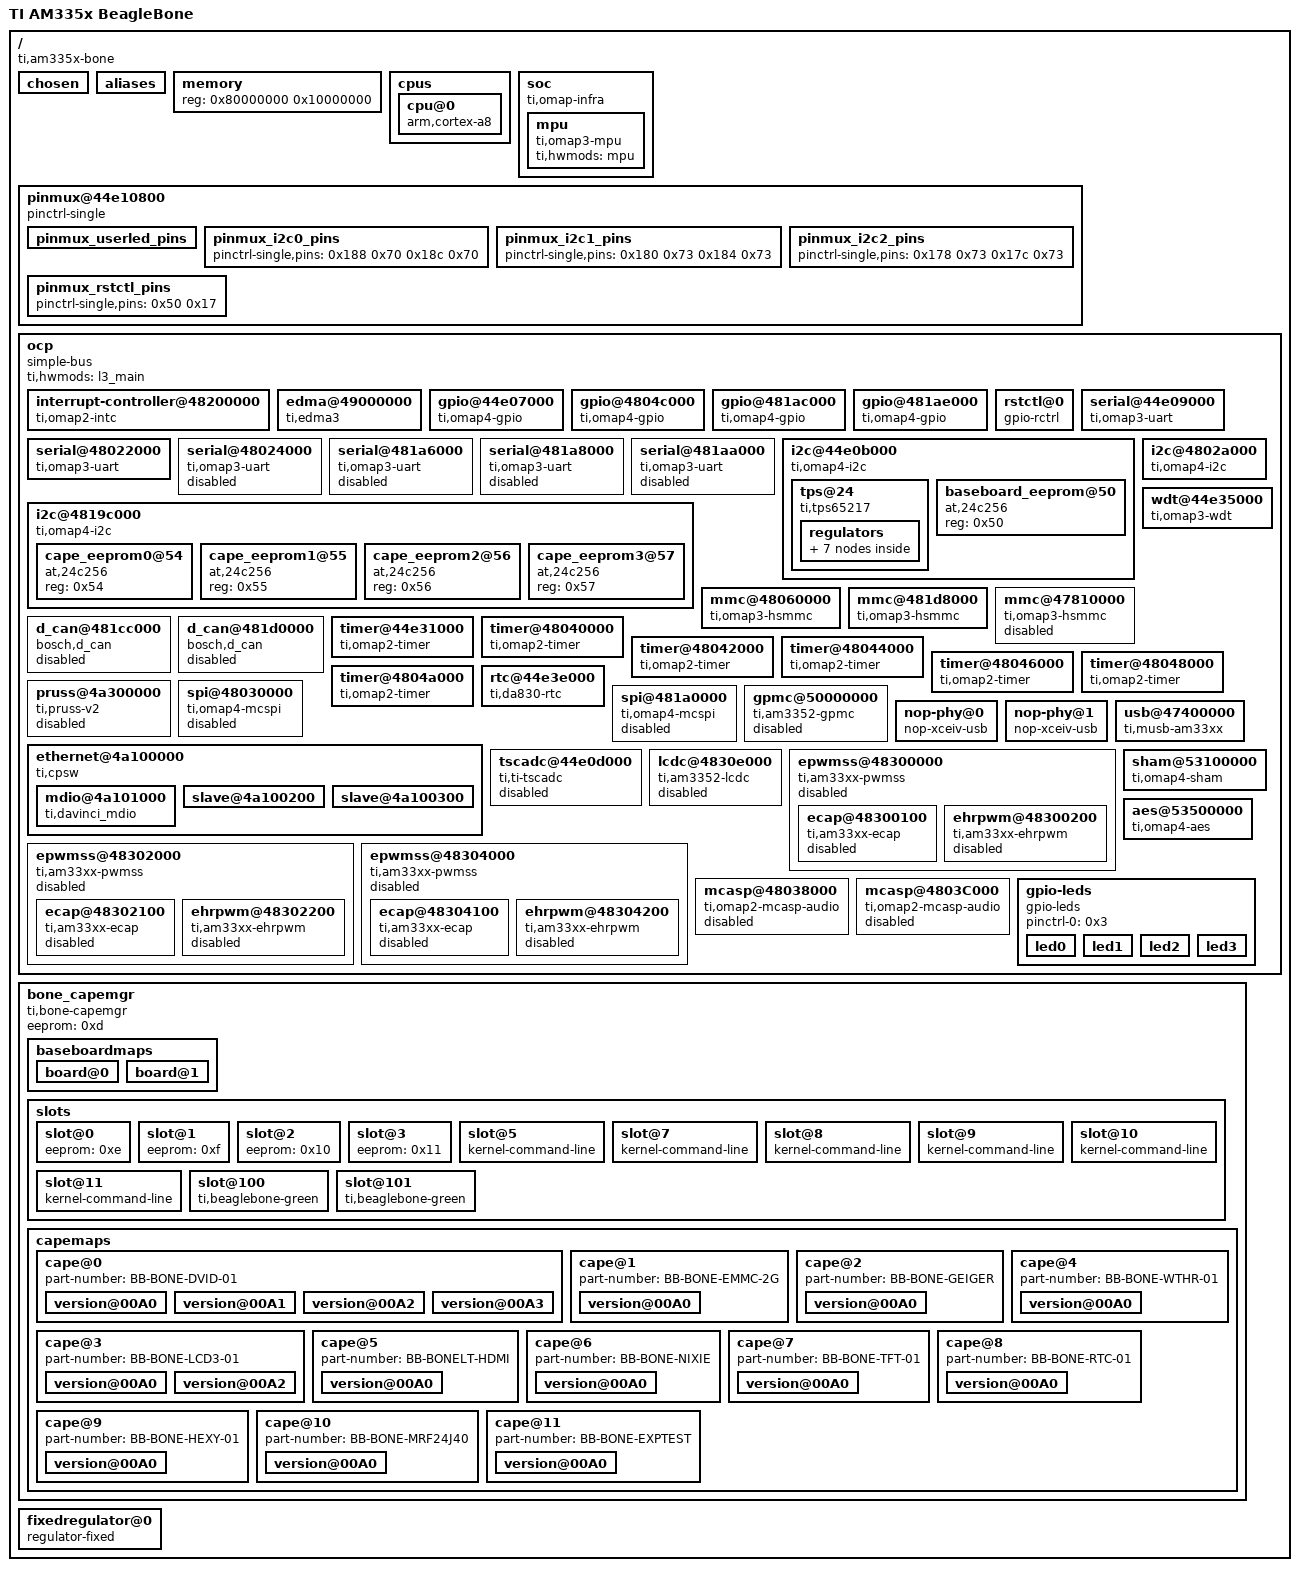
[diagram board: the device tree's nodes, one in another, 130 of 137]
/dts-v1/;

/ {
	#address-cells = <0x1>;
	#size-cells = <0x1>;
	compatible = "ti,am335x-bone", "ti,am33xx";
	interrupt-parent = <0x1>;
	model = "TI AM335x BeagleBone";

	chosen {
	};

	aliases {
		serial0 = "/ocp/serial@44e09000";
		serial1 = "/ocp/serial@48022000";
		serial2 = "/ocp/serial@48024000";
		serial3 = "/ocp/serial@481a6000";
		serial4 = "/ocp/serial@481a8000";
		serial5 = "/ocp/serial@481aa000";
	};

	memory {
		device_type = "memory";
		reg = <0x80000000 0x10000000>;
	};

	cpus {

		cpu@0 {
			compatible = "arm,cortex-a8";
			operating-points = <0xf4240 0x149970 0xc3500 0x13d620 0x927c0 0x10f7c0 0x493e0 0xec928>;
			voltage-tolerance = <0x2>;
			clock-latency = <0x493e0>;
			cpu0-supply = <0x2>;
			linux,phandle = <0x12>;
			phandle = <0x12>;
		};
	};

	soc {
		compatible = "ti,omap-infra";

		mpu {
			compatible = "ti,omap3-mpu";
			ti,hwmods = "mpu";
		};
	};

	pinmux@44e10800 {
		compatible = "pinctrl-single";
		reg = <0x44e10800 0x238>;
		#address-cells = <0x1>;
		#size-cells = <0x0>;
		pinctrl-single,register-width = <0x20>;
		pinctrl-single,function-mask = <0x7f>;
		pinctrl-names = "default";
		pinctrl-0 = <0x3>;
		linux,phandle = <0x13>;
		phandle = <0x13>;

		pinmux_userled_pins {
			pinctrl-single,pins = <0x54 0x7 0x58 0x17 0x5c 0x7 0x60 0x17
// /*PRU1 GPO 0-7*/ 0xa0 0x05 0xa4 0x05 0xa8 0x05 0xac 0x05 0xb0 0x05 0xb4 0x05 0xb8 0x05 0xbc 0x05
/*GPIOrt pins*/ 0x90 0x27 0x94 0x27 0x9c 0x27 0x98 0x27 0x34 0x27 0x30 0x27 0x78 0x27 0x48 0x27 0x3c 0x27 0x38 0x27 0x4c 0x27 0x8c 0x27 0xe0 0x27 0xe8 0x27 0xe4 0x27 0xec 0x27
// /*GPIOrt pins with PRU0 gpo*/ 0x90 0x27 0x94 0x27 0x9c 0x27 0x98 0x27 0x34 0x06 0x30 0x06 0x78 0x27 0x48 0x27 0x3c 0x27 0x38 0x27 0x4c 0x27 0x8c 0x27 0xe0 0x27 0xe8 0x27 0xe4 0x27 0xec 0x27
>;
			linux,phandle = <0x3>;
			phandle = <0x3>;
		};

		pinmux_i2c0_pins {
			pinctrl-single,pins = <0x188 0x70 0x18c 0x70>;
			linux,phandle = <0x6>;
			phandle = <0x6>;
		};

		pinmux_i2c1_pins {
			pinctrl-single,pins = <0x180 0x73 0x184 0x73>;
			linux,phandle = <0x7>;
			phandle = <0x7>;
		};

		pinmux_i2c2_pins {
			pinctrl-single,pins = <0x178 0x73 0x17c 0x73>;
			linux,phandle = <0x8>;
			phandle = <0x8>;
		};

		pinmux_rstctl_pins {
			pinctrl-single,pins = <0x50 0x17>;
			linux,phandle = <0x4>;
			phandle = <0x4>;
		};
	};

	ocp {
		compatible = "simple-bus";
		#address-cells = <0x1>;
		#size-cells = <0x1>;
		ranges;
		ti,hwmods = "l3_main";
		linux,phandle = <0x14>;
		phandle = <0x14>;

		interrupt-controller@48200000 {
			compatible = "ti,omap2-intc";
			interrupt-controller;
			#interrupt-cells = <0x1>;
			ti,intc-size = <0x80>;
			reg = <0x48200000 0x1000>;
			linux,phandle = <0x1>;
			phandle = <0x1>;
		};

		edma@49000000 {
			compatible = "ti,edma3";
			ti,hwmods = "tpcc", "tptc0", "tptc1", "tptc2";
			reg = <0x49000000 0x10000 0x44e10f90 0x40>;
			interrupt-parent = <0x1>;
			interrupts = <0xc 0xd 0xe>;
			#dma-cells = <0x1>;
			dma-channels = <0x40>;
			ti,edma-regions = <0x4>;
			ti,edma-slots = <0x100>;
			ti,edma-queue-tc-map = <0x0 0x0 0x1 0x1 0x2 0x2>;
			ti,edma-queue-priority-map = <0x0 0x0 0x1 0x1 0x2 0x2>;
			ti,edma-default-queue = <0x1>;
			ti,edma-xbar-event-map = <0x20 0xc 0x1e 0x14>;
			linux,phandle = <0x9>;
			phandle = <0x9>;
		};

		gpio@44e07000 {
			compatible = "ti,omap4-gpio";
			ti,hwmods = "gpio1";
			gpio-controller;
			#gpio-cells = <0x2>;
			interrupt-controller;
			#interrupt-cells = <0x1>;
			reg = <0x44e07000 0x1000>;
			interrupts = <0x60>;
			linux,phandle = <0x15>;
			phandle = <0x15>;
		};

		gpio@4804c000 {
			compatible = "ti,omap4-gpio";
			ti,hwmods = "gpio2";
			gpio-controller;
			#gpio-cells = <0x2>;
			interrupt-controller;
			#interrupt-cells = <0x1>;
			reg = <0x4804c000 0x1000>;
			interrupts = <0x62>;
			linux,phandle = <0x5>;
			phandle = <0x5>;
		};

		gpio@481ac000 {
			compatible = "ti,omap4-gpio";
			ti,hwmods = "gpio3";
			gpio-controller;
			#gpio-cells = <0x2>;
			interrupt-controller;
			#interrupt-cells = <0x1>;
			reg = <0x481ac000 0x1000>;
			interrupts = <0x20>;
			linux,phandle = <0x16>;
			phandle = <0x16>;
		};

		gpio@481ae000 {
			compatible = "ti,omap4-gpio";
			ti,hwmods = "gpio4";
			gpio-controller;
			#gpio-cells = <0x2>;
			interrupt-controller;
			#interrupt-cells = <0x1>;
			reg = <0x481ae000 0x1000>;
			interrupts = <0x3e>;
			linux,phandle = <0x17>;
			phandle = <0x17>;
		};

		rstctl@0 {
			status = "okay";
			compatible = "gpio-rctrl";
			pinctrl-names = "default";
			pinctrl-0 = <0x4>;
			#reset-cells = <0x2>;
			gpios = <0x5 0x14 0x0>;
			gpio-names = "eMMC_RSTn";
			linux,phandle = <0xb>;
			phandle = <0xb>;
		};

		serial@44e09000 {
			compatible = "ti,omap3-uart";
			ti,hwmods = "uart1";
			clock-frequency = <0x2dc6c00>;
			reg = <0x44e09000 0x2000>;
			interrupts = <0x48>;
			status = "okay";
			linux,phandle = <0x18>;
			phandle = <0x18>;
		};

		serial@48022000 {
			compatible = "ti,omap3-uart";
			ti,hwmods = "uart2";
			clock-frequency = <0x2dc6c00>;
			reg = <0x48022000 0x2000>;
			interrupts = <0x49>;
			status = "okay";
			linux,phandle = <0x19>;
			phandle = <0x19>;
		};

		serial@48024000 {
			compatible = "ti,omap3-uart";
			ti,hwmods = "uart3";
			clock-frequency = <0x2dc6c00>;
			reg = <0x48024000 0x2000>;
			interrupts = <0x4a>;
			status = "disabled";
			linux,phandle = <0x1a>;
			phandle = <0x1a>;
		};

		serial@481a6000 {
			compatible = "ti,omap3-uart";
			ti,hwmods = "uart4";
			clock-frequency = <0x2dc6c00>;
			reg = <0x481a6000 0x2000>;
			interrupts = <0x2c>;
			status = "disabled";
			linux,phandle = <0x1b>;
			phandle = <0x1b>;
		};

		serial@481a8000 {
			compatible = "ti,omap3-uart";
			ti,hwmods = "uart5";
			clock-frequency = <0x2dc6c00>;
			reg = <0x481a8000 0x2000>;
			interrupts = <0x2d>;
			status = "disabled";
			linux,phandle = <0x1c>;
			phandle = <0x1c>;
		};

		serial@481aa000 {
			compatible = "ti,omap3-uart";
			ti,hwmods = "uart6";
			clock-frequency = <0x2dc6c00>;
			reg = <0x481aa000 0x2000>;
			interrupts = <0x2e>;
			status = "disabled";
			linux,phandle = <0x1d>;
			phandle = <0x1d>;
		};

		i2c@44e0b000 {
			compatible = "ti,omap4-i2c";
			#address-cells = <0x1>;
			#size-cells = <0x0>;
			ti,hwmods = "i2c1";
			reg = <0x44e0b000 0x1000>;
			interrupts = <0x46>;
			status = "okay";
			clock-frequency = <0x61a80>;
			pinctrl-names = "default";
			pinctrl-0 = <0x6>;
			linux,phandle = <0x1e>;
			phandle = <0x1e>;

			tps@24 {
				reg = <0x24>;
				compatible = "ti,tps65217";
				ti,pmic-shutdown-controller;
				linux,phandle = <0x1f>;
				phandle = <0x1f>;

				regulators {
					#address-cells = <0x1>;
					#size-cells = <0x0>;

					regulator@0 {
						reg = <0x0>;
						regulator-compatible = "dcdc1";
						regulator-always-on;
						linux,phandle = <0x20>;
						phandle = <0x20>;
					};

					regulator@1 {
						reg = <0x1>;
						regulator-compatible = "dcdc2";
						regulator-name = "vdd_mpu";
						regulator-min-microvolt = <0xe1d48>;
						regulator-max-microvolt = <0x1437c8>;
						regulator-boot-on;
						regulator-always-on;
						linux,phandle = <0x2>;
						phandle = <0x2>;
					};

					regulator@2 {
						reg = <0x2>;
						regulator-compatible = "dcdc3";
						regulator-name = "vdd_core";
						regulator-min-microvolt = <0xe1d48>;
						regulator-max-microvolt = <0x118c30>;
						regulator-boot-on;
						regulator-always-on;
						linux,phandle = <0x21>;
						phandle = <0x21>;
					};

					regulator@3 {
						reg = <0x3>;
						regulator-compatible = "ldo1";
						regulator-always-on;
						linux,phandle = <0x22>;
						phandle = <0x22>;
					};

					regulator@4 {
						reg = <0x4>;
						regulator-compatible = "ldo2";
						regulator-always-on;
						linux,phandle = <0x23>;
						phandle = <0x23>;
					};

					regulator@5 {
						reg = <0x5>;
						regulator-compatible = "ldo3";
						regulator-min-microvolt = <0x1b7740>;
						regulator-max-microvolt = <0x1b7740>;
						regulator-always-on;
						linux,phandle = <0x24>;
						phandle = <0x24>;
					};

					regulator@6 {
						reg = <0x6>;
						regulator-compatible = "ldo4";
						regulator-always-on;
						linux,phandle = <0x25>;
						phandle = <0x25>;
					};
				};
			};

			baseboard_eeprom@50 {
				compatible = "at,24c256";
				reg = <0x50>;
				linux,phandle = <0xd>;
				phandle = <0xd>;
			};
		};

		i2c@4802a000 {
			compatible = "ti,omap4-i2c";
			#address-cells = <0x1>;
			#size-cells = <0x0>;
			ti,hwmods = "i2c2";
			reg = <0x4802a000 0x1000>;
			interrupts = <0x47>;
			status = "okay";
			pinctrl-names = "default";
			pinctrl-0 = <0x7>;
			clock-frequency = <0x61a80>;
			linux,phandle = <0x26>;
			phandle = <0x26>;
		};

		i2c@4819c000 {
			compatible = "ti,omap4-i2c";
			#address-cells = <0x1>;
			#size-cells = <0x0>;
			ti,hwmods = "i2c3";
			reg = <0x4819c000 0x1000>;
			interrupts = <0x1e>;
			status = "okay";
			pinctrl-names = "default";
			pinctrl-0 = <0x8>;
			clock-frequency = <0x186a0>;
			linux,phandle = <0x27>;
			phandle = <0x27>;

			cape_eeprom0@54 {
				compatible = "at,24c256";
				reg = <0x54>;
				linux,phandle = <0xe>;
				phandle = <0xe>;
			};

			cape_eeprom1@55 {
				compatible = "at,24c256";
				reg = <0x55>;
				linux,phandle = <0xf>;
				phandle = <0xf>;
			};

			cape_eeprom2@56 {
				compatible = "at,24c256";
				reg = <0x56>;
				linux,phandle = <0x10>;
				phandle = <0x10>;
			};

			cape_eeprom3@57 {
				compatible = "at,24c256";
				reg = <0x57>;
				linux,phandle = <0x11>;
				phandle = <0x11>;
			};
		};

		mmc@48060000 {
			compatible = "ti,omap3-hsmmc";
			ti,hwmods = "mmc1";
			ti,dual-volt;
			ti,needs-special-reset;
			ti,needs-special-hs-handling;
			dmas = <0x9 0x18 0x9 0x19>;
			dma-names = "tx", "rx";
			status = "okay";
			vmmc-supply = <0xa>;
			ti,vcc-aux-disable-is-sleep;
			linux,phandle = <0x28>;
			phandle = <0x28>;
		};

		mmc@481d8000 {
			compatible = "ti,omap3-hsmmc";
			ti,hwmods = "mmc2";
			ti,needs-special-reset;
			ti,needs-special-hs-handling;
			dmas = <0x9 0x2 0x9 0x3>;
			dma-names = "tx", "rx";
			status = "okay";
			vmmc-supply = <0xa>;
			bus-width = <0x8>;
			ti,non-removable;
			reset = <0xb 0x0 0x0>;
			reset-names = "eMMC_RSTn-CONSUMER";
			linux,phandle = <0x29>;
			phandle = <0x29>;
		};

		mmc@47810000 {
			compatible = "ti,omap3-hsmmc";
			ti,hwmods = "mmc3";
			ti,needs-special-reset;
			ti,needs-special-hs-handling;
			status = "disabled";
			linux,phandle = <0x2a>;
			phandle = <0x2a>;
		};

		wdt@44e35000 {
			compatible = "ti,omap3-wdt";
			ti,hwmods = "wd_timer2";
			reg = <0x44e35000 0x1000>;
			interrupts = <0x5b>;
			linux,phandle = <0x2b>;
			phandle = <0x2b>;
		};

		d_can@481cc000 {
			compatible = "bosch,d_can";
			ti,hwmods = "d_can0";
			reg = <0x481cc000 0x2000>;
			interrupts = <0x34>;
			status = "disabled";
			linux,phandle = <0x2c>;
			phandle = <0x2c>;
		};

		d_can@481d0000 {
			compatible = "bosch,d_can";
			ti,hwmods = "d_can1";
			reg = <0x481d0000 0x2000>;
			interrupts = <0x37>;
			status = "disabled";
			linux,phandle = <0x2d>;
			phandle = <0x2d>;
		};

		timer@44e31000 {
			compatible = "ti,omap2-timer";
			reg = <0x44e31000 0x400>;
			interrupts = <0x43>;
			ti,hwmods = "timer1";
			ti,timer-alwon;
			linux,phandle = <0x2e>;
			phandle = <0x2e>;
		};

		timer@48040000 {
			compatible = "ti,omap2-timer";
			reg = <0x48040000 0x400>;
			interrupts = <0x44>;
			ti,hwmods = "timer2";
			linux,phandle = <0x2f>;
			phandle = <0x2f>;
		};

		timer@48042000 {
			compatible = "ti,omap2-timer";
			reg = <0x48042000 0x400>;
			interrupts = <0x45>;
			ti,hwmods = "timer3";
			linux,phandle = <0x30>;
			phandle = <0x30>;
		};

		timer@48044000 {
			compatible = "ti,omap2-timer";
			reg = <0x48044000 0x400>;
			interrupts = <0x5c>;
			ti,hwmods = "timer4";
			ti,timer-pwm;
			linux,phandle = <0x31>;
			phandle = <0x31>;
		};

		timer@48046000 {
			compatible = "ti,omap2-timer";
			reg = <0x48046000 0x400>;
			interrupts = <0x5d>;
			ti,hwmods = "timer5";
			ti,timer-pwm;
			linux,phandle = <0x32>;
			phandle = <0x32>;
		};

		timer@48048000 {
			compatible = "ti,omap2-timer";
			reg = <0x48048000 0x400>;
			interrupts = <0x5e>;
			ti,hwmods = "timer6";
			ti,timer-pwm;
			linux,phandle = <0x33>;
			phandle = <0x33>;
		};

		timer@4804a000 {
			compatible = "ti,omap2-timer";
			reg = <0x4804a000 0x400>;
			interrupts = <0x5f>;
			ti,hwmods = "timer7";
			ti,timer-pwm;
			linux,phandle = <0x34>;
			phandle = <0x34>;
		};

		pruss@4a300000 {
			compatible = "ti,pruss-v2";
			ti,hwmods = "pruss";
			ti,deassert-hard-reset = "pruss", "pruss";
			reg = <0x4a300000 0x80000>;
			ti,pintc-offset = <0x20000>;
			interrupt-parent = <0x1>;
			status = "disabled";
			interrupts = <0x14 0x15 0x16 0x17 0x18 0x19 0x1a 0x1b>;
			linux,phandle = <0x35>;
			phandle = <0x35>;
		};

		rtc@44e3e000 {
			compatible = "ti,da830-rtc";
			reg = <0x44e3e000 0x1000>;
			interrupts = <0x4b 0x4c>;
			ti,hwmods = "rtc";
			ti,system-power-controller;
		};

		spi@48030000 {
			compatible = "ti,omap4-mcspi";
			#address-cells = <0x1>;
			#size-cells = <0x0>;
			reg = <0x48030000 0x400>;
			interrupt = <0x41>;
			ti,spi-num-cs = <0x2>;
			ti,hwmods = "spi0";
			dmas = <0x9 0x10 0x9 0x11 0x9 0x12 0x9 0x13>;
			dma-names = "tx0", "rx0", "tx1", "rx1";
			status = "disabled";
			linux,phandle = <0x36>;
			phandle = <0x36>;
		};

		spi@481a0000 {
			compatible = "ti,omap4-mcspi";
			#address-cells = <0x1>;
			#size-cells = <0x0>;
			reg = <0x481a0000 0x400>;
			interrupt = <0x7d>;
			ti,spi-num-cs = <0x2>;
			ti,hwmods = "spi1";
			dmas = <0x9 0x2a 0x9 0x2b 0x9 0x2c 0x9 0x2d>;
			dma-names = "tx0", "rx0", "tx1", "rx1";
			status = "disabled";
			linux,phandle = <0x37>;
			phandle = <0x37>;
		};

		gpmc@50000000 {
			compatible = "ti,am3352-gpmc";
			ti,hwmods = "gpmc";
			reg = <0x50000000 0x1000000>;
			interrupts = <0x64>;
			gpmc,num-cs = <0x7>;
			gpmc,num-waitpins = <0x2>;
			#address-cells = <0x2>;
			#size-cells = <0x1>;
			status = "disabled";
			linux,phandle = <0x38>;
			phandle = <0x38>;
		};

		nop-phy@0 {
			compatible = "nop-xceiv-usb";
		};

		nop-phy@1 {
			compatible = "nop-xceiv-usb";
		};

		usb@47400000 {
			compatible = "ti,musb-am33xx";
			reg = <0x47400000 0x1000 0x47401000 0x800 0x47401800 0x800>;
			interrupts = <0x11 0x12 0x13>;
			multipoint = <0x1>;
			num-eps = <0x10>;
			ram-bits = <0xc>;
			port0-mode = <0x3>;
			port1-mode = <0x1>;
			power = <0xfa>;
			ti,hwmods = "usb_otg_hs";
			status = "okay";
			interface_type = <0x1>;
			linux,phandle = <0x39>;
			phandle = <0x39>;
		};

		ethernet@4a100000 {
			compatible = "ti,cpsw";
			ti,hwmods = "cpgmac0";
			cpdma_channels = <0x8>;
			ale_entries = <0x400>;
			bd_ram_size = <0x2000>;
			no_bd_ram = <0x0>;
			rx_descs = <0x40>;
			mac_control = <0x20>;
			slaves = <0x2>;
			cpts_active_slave = <0x0>;
			cpts_clock_mult = <0x80000000>;
			cpts_clock_shift = <0x1d>;
			reg = <0x4a100000 0x800 0x4a101200 0x100>;
			#address-cells = <0x1>;
			#size-cells = <0x1>;
			interrupt-parent = <0x1>;
			interrupts = <0x28 0x29 0x2a 0x2b>;
			ranges;
			disable-napi;
			linux,phandle = <0x3a>;
			phandle = <0x3a>;

			mdio@4a101000 {
				compatible = "ti,davinci_mdio";
				#address-cells = <0x1>;
				#size-cells = <0x0>;
				ti,hwmods = "davinci_mdio";
				bus_freq = <0xf4240>;
				reg = <0x4a101000 0x100>;
				linux,phandle = <0xc>;
				phandle = <0xc>;
			};

			slave@4a100200 {
				mac-address = [00 00 00 00 00 00];
				phy_id = <0xc 0x0>;
				linux,phandle = <0x3b>;
				phandle = <0x3b>;
			};

			slave@4a100300 {
				mac-address = [00 00 00 00 00 00];
				phy_id = <0xc 0x1>;
				linux,phandle = <0x3c>;
				phandle = <0x3c>;
			};
		};

		tscadc@44e0d000 {
			compatible = "ti,ti-tscadc";
			reg = <0x44e0d000 0x1000>;
			interrupt-parent = <0x1>;
			interrupts = <0x10>;
			ti,hwmods = "adc_tsc";
			status = "disabled";
			linux,phandle = <0x3d>;
			phandle = <0x3d>;
		};

		lcdc@4830e000 {
			compatible = "ti,am3352-lcdc", "ti,da830-lcdc";
			reg = <0x4830e000 0x1000>;
			interrupts = <0x24>;
			status = "disabled";
			ti,hwmods = "lcdc";
			linux,phandle = <0x3e>;
			phandle = <0x3e>;
		};

		epwmss@48300000 {
			compatible = "ti,am33xx-pwmss";
			reg = <0x48300000 0x10>;
			ti,hwmods = "epwmss0";
			#address-cells = <0x1>;
			#size-cells = <0x1>;
			status = "disabled";
			ranges = <0x48300100 0x48300100 0x80 0x48300180 0x48300180 0x80 0x48300200 0x48300200 0x80>;
			linux,phandle = <0x3f>;
			phandle = <0x3f>;

			ecap@48300100 {
				compatible = "ti,am33xx-ecap";
				#pwm-cells = <0x3>;
				reg = <0x48300100 0x80>;
				ti,hwmods = "ecap0";
				status = "disabled";
				linux,phandle = <0x40>;
				phandle = <0x40>;
			};

			ehrpwm@48300200 {
				compatible = "ti,am33xx-ehrpwm";
				#pwm-cells = <0x3>;
				reg = <0x48300200 0x80>;
				ti,hwmods = "ehrpwm0";
				status = "disabled";
				linux,phandle = <0x41>;
				phandle = <0x41>;
			};
		};

		epwmss@48302000 {
			compatible = "ti,am33xx-pwmss";
			reg = <0x48302000 0x10>;
			ti,hwmods = "epwmss1";
			#address-cells = <0x1>;
			#size-cells = <0x1>;
			status = "disabled";
			ranges = <0x48302100 0x48302100 0x80 0x48302180 0x48302180 0x80 0x48302200 0x48302200 0x80>;
			linux,phandle = <0x42>;
			phandle = <0x42>;

			ecap@48302100 {
				compatible = "ti,am33xx-ecap";
				#pwm-cells = <0x3>;
				reg = <0x48302100 0x80>;
				ti,hwmods = "ecap1";
				status = "disabled";
				linux,phandle = <0x43>;
				phandle = <0x43>;
			};

			ehrpwm@48302200 {
				compatible = "ti,am33xx-ehrpwm";
				#pwm-cells = <0x3>;
				reg = <0x48302200 0x80>;
				ti,hwmods = "ehrpwm1";
				status = "disabled";
				linux,phandle = <0x44>;
				phandle = <0x44>;
			};
		};

		epwmss@48304000 {
			compatible = "ti,am33xx-pwmss";
			reg = <0x48304000 0x10>;
			ti,hwmods = "epwmss2";
			#address-cells = <0x1>;
			#size-cells = <0x1>;
			status = "disabled";
			ranges = <0x48304100 0x48304100 0x80 0x48304180 0x48304180 0x80 0x48304200 0x48304200 0x80>;
			linux,phandle = <0x45>;
			phandle = <0x45>;

			ecap@48304100 {
				compatible = "ti,am33xx-ecap";
				#pwm-cells = <0x3>;
				reg = <0x48304100 0x80>;
				ti,hwmods = "ecap2";
				status = "disabled";
				linux,phandle = <0x46>;
				phandle = <0x46>;
			};

			ehrpwm@48304200 {
				compatible = "ti,am33xx-ehrpwm";
				#pwm-cells = <0x3>;
				reg = <0x48304200 0x80>;
				ti,hwmods = "ehrpwm2";
				status = "disabled";
				linux,phandle = <0x47>;
				phandle = <0x47>;
			};
		};

		sham@53100000 {
			compatible = "ti,omap4-sham";
			ti,hwmods = "sham";
			#address-cells = <0x1>;
			#size-cells = <0x0>;
			reg = <0x53100000 0x200>;
			interrupt-parent = <0x1>;
			interrupts = <0x6d>;
			dmas = <0x9 0x24>;
			dma-names = "rx";
			status = "okay";
			linux,phandle = <0x48>;
			phandle = <0x48>;
		};

		aes@53500000 {
			compatible = "ti,omap4-aes";
			ti,hwmods = "aes";
			#address-cells = <0x1>;
			#size-cells = <0x0>;
			reg = <0x53500000 0xa0>;
			interrupt-parent = <0x1>;
			interrupts = <0x66>;
			dmas = <0x9 0x6 0x9 0x5>;
			dma-names = "tx", "rx";
			status = "okay";
			linux,phandle = <0x49>;
			phandle = <0x49>;
		};

		mcasp@48038000 {
			compatible = "ti,omap2-mcasp-audio";
			#address-cells = <0x1>;
			#size-cells = <0x0>;
			ti,hwmods = "mcasp0";
			reg = <0x48038000 0x2000>;
			interrupts = <0x50 0x51>;
			status = "disabled";
			asp-chan-q = <0x2>;
			tx-dma-offset = <0x46000000>;
			rx-dma-offset = <0x46000000>;
			dmas = <0x9 0x8 0x9 0x9>;
			dma-names = "tx", "rx";
			linux,phandle = <0x4a>;
			phandle = <0x4a>;
		};

		mcasp@4803C000 {
			compatible = "ti,omap2-mcasp-audio";
			#address-cells = <0x1>;
			#size-cells = <0x0>;
			ti,hwmods = "mcasp1";
			reg = <0x4803c000 0x2000>;
			interrupts = <0x52 0x53>;
			status = "disabled";
			asp-chan-q = <0x2>;
			tx-dma-offset = <0x46400000>;
			rx-dma-offset = <0x46400000>;
			dmas = <0x9 0xa 0x9 0xb>;
			dma-names = "tx", "rx";
			linux,phandle = <0x4b>;
			phandle = <0x4b>;
		};

		gpio-leds {
			compatible = "gpio-leds";
			pinctrl-names = "default";
			pinctrl-0 = <0x3>;

			led0 {
				label = "beaglebone:green:usr0";
				gpios = <0x5 0x15 0x0>;
				linux,default-trigger = "heartbeat";
				default-state = "off";
			};

			led1 {
				label = "beaglebone:green:usr1";
				gpios = <0x5 0x16 0x0>;
				linux,default-trigger = "mmc0";
				default-state = "off";
			};

			led2 {
				label = "beaglebone:green:usr2";
				gpios = <0x5 0x17 0x0>;
				linux,default-trigger = "cpu0";
				default-state = "off";
			};

			led3 {
				label = "beaglebone:green:usr3";
				gpios = <0x5 0x18 0x0>;
				default-state = "off";
				linux,default-trigger = "mmc1";
			};
		};
	};

	bone_capemgr {
		compatible = "ti,bone-capemgr";
		status = "okay";
		eeprom = <0xd>;

		baseboardmaps {

			board@0 {
				board-name = "A335BONE";
				compatible-name = "ti,beaglebone";
				linux,phandle = <0x4c>;
				phandle = <0x4c>;
			};

			board@1 {
				board-name = "A335BNLT";
				compatible-name = "ti,beaglebone-green";
				linux,phandle = <0x4d>;
				phandle = <0x4d>;
			};
		};

		slots {

			slot@0 {
				eeprom = <0xe>;
			};

			slot@1 {
				eeprom = <0xf>;
			};

			slot@2 {
				eeprom = <0x10>;
			};

			slot@3 {
				eeprom = <0x11>;
			};

			slot@5 {
				ti,cape-override;
				compatible = "kernel-command-line", "runtime";
				board-name = "Bone-Geiger";
				version = "00A0";
				manufacturer = "Geiger Inc.";
				part-number = "BB-BONE-GEIGER";
			};

			slot@7 {
				ti,cape-override;
				compatible = "kernel-command-line", "runtime";
				board-name = "Bone-Nixie";
				version = "00A0";
				manufacturer = "Ranostay Industries";
				part-number = "BB-BONE-NIXIE";
			};

			slot@8 {
				ti,cape-override;
				compatible = "kernel-command-line", "runtime";
				board-name = "Bone-TFT";
				version = "00A0";
				manufacturer = "Adafruit";
				part-number = "BB-BONE-TFT-01";
			};

			slot@9 {
				ti,cape-override;
				compatible = "kernel-command-line", "runtime";
				board-name = "Bone-RTC";
				version = "00A0";
				manufacturer = "Adafruit";
				part-number = "BB-BONE-RTC-01";
			};

			slot@10 {
				ti,cape-override;
				compatible = "kernel-command-line", "runtime";
				board-name = "Bone-Hexy";
				version = "00A0";
				manufacturer = "Koen Kooi";
				part-number = "BB-BONE-HEXY-01";
			};

			slot@11 {
				ti,cape-override;
				compatible = "kernel-command-line", "runtime";
				board-name = "Bone-MRF24J40";
				version = "00A0";
				manufacturer = "Signal 11 Software";
				part-number = "BB-BONE-MRF24J40";
			};

			slot@100 {
				ti,cape-override;
				priority = <0x1>;
				compatible = "ti,beaglebone-green";
				board-name = "Bone-LT-eMMC-2G";
				version = "00A0";
				manufacturer = "Texas Instruments";
				part-number = "BB-BONE-EMMC-2G";
			};

			slot@101 {
				ti,cape-override;
				priority = <0x1>;
				compatible = "ti,beaglebone-green";
				board-name = "Bone-Black-HDMI";
				version = "00A0";
				manufacturer = "Texas Instruments";
				part-number = "BB-BONELT-HDMI";
			};
		};

		capemaps {

			cape@0 {
				part-number = "BB-BONE-DVID-01";

				version@00A0 {
					version = "00A0";
					dtbo = "cape-bone-dvi-00A0.dtbo";
				};

				version@00A1 {
					version = "00A1", "01";
					dtbo = "cape-bone-dvi-00A1.dtbo";
				};

				version@00A2 {
					version = "00A2", "A2";
					dtbo = "cape-bone-dvi-00A2.dtbo";
				};

				version@00A3 {
					version = "00A3";
					dtbo = "cape-bone-dvi-00A2.dtbo";
				};
			};

			cape@1 {
				part-number = "BB-BONE-EMMC-2G";

				version@00A0 {
					version = "00A0";
					dtbo = "cape-bone-2g-emmc1.dtbo";
				};
			};

			cape@2 {
				part-number = "BB-BONE-GEIGER";

				version@00A0 {
					version = "00A0";
					dtbo = "cape-bone-geiger-00A0.dtbo";
				};
			};

			cape@3 {
				part-number = "BB-BONE-LCD3-01";

				version@00A0 {
					version = "00A0";
					dtbo = "cape-bone-lcd3-00A0.dtbo";
				};

				version@00A2 {
					version = "00A2";
					dtbo = "cape-bone-lcd3-00A2.dtbo";
				};
			};

			cape@4 {
				part-number = "BB-BONE-WTHR-01";

				version@00A0 {
					version = "00A0";
					dtbo = "cape-bone-weather-00A0.dtbo";
				};
			};

			cape@5 {
				part-number = "BB-BONELT-HDMI";

				version@00A0 {
					version = "00A0";
					dtbo = "cape-boneblack-hdmi-00A0.dtbo";
				};
			};

			cape@6 {
				part-number = "BB-BONE-NIXIE";

				version@00A0 {
					version = "00A0";
					dtbo = "cape-bone-nixie-00A0.dtbo";
				};
			};

			cape@7 {
				part-number = "BB-BONE-TFT-01";

				version@00A0 {
					version = "00A0";
					dtbo = "cape-bone-adafruit-lcd-00A0.dtbo";
				};
			};

			cape@8 {
				part-number = "BB-BONE-RTC-01";

				version@00A0 {
					version = "00A0";
					dtbo = "cape-bone-adafruit-rtc-00A0.dtbo";
				};
			};

			cape@9 {
				part-number = "BB-BONE-HEXY-01";

				version@00A0 {
					version = "00A0";
					dtbo = "cape-bone-hexy-00A0.dtbo";
				};
			};

			cape@10 {
				part-number = "BB-BONE-MRF24J40";

				version@00A0 {
					version = "00A0";
					dtbo = "cape-bone-mrf24j40-00A0.dtbo";
				};
			};

			cape@11 {
				part-number = "BB-BONE-EXPTEST";

				version@00A0 {
					version = "00A0";
					dtbo = "cape-bone-exptest-00A0.dtbo";
				};
			};
		};
	};

	fixedregulator@0 {
		compatible = "regulator-fixed";
		regulator-name = "vmmcsd_fixed";
		regulator-min-microvolt = <0x325aa0>;
		regulator-max-microvolt = <0x325aa0>;
		linux,phandle = <0xa>;
		phandle = <0xa>;
	};

	__symbols__ {
		cpu = "/cpus/cpu@0";
		am33xx_pinmux = "/pinmux@44e10800";
		userled_pins = "/pinmux@44e10800/pinmux_userled_pins";
		i2c0_pins = "/pinmux@44e10800/pinmux_i2c0_pins";
		i2c1_pins = "/pinmux@44e10800/pinmux_i2c1_pins";
		i2c2_pins = "/pinmux@44e10800/pinmux_i2c2_pins";
		rstctl_pins = "/pinmux@44e10800/pinmux_rstctl_pins";
		ocp = "/ocp";
		intc = "/ocp/interrupt-controller@48200000";
		edma = "/ocp/edma@49000000";
		gpio1 = "/ocp/gpio@44e07000";
		gpio2 = "/ocp/gpio@4804c000";
		gpio3 = "/ocp/gpio@481ac000";
		gpio4 = "/ocp/gpio@481ae000";
		rstctl = "/ocp/rstctl@0";
		uart1 = "/ocp/serial@44e09000";
		uart2 = "/ocp/serial@48022000";
		uart3 = "/ocp/serial@48024000";
		uart4 = "/ocp/serial@481a6000";
		uart5 = "/ocp/serial@481a8000";
		uart6 = "/ocp/serial@481aa000";
		i2c0 = "/ocp/i2c@44e0b000";
		tps = "/ocp/i2c@44e0b000/tps@24";
		dcdc1_reg = "/ocp/i2c@44e0b000/tps@24/regulators/regulator@0";
		dcdc2_reg = "/ocp/i2c@44e0b000/tps@24/regulators/regulator@1";
		dcdc3_reg = "/ocp/i2c@44e0b000/tps@24/regulators/regulator@2";
		ldo1_reg = "/ocp/i2c@44e0b000/tps@24/regulators/regulator@3";
		ldo2_reg = "/ocp/i2c@44e0b000/tps@24/regulators/regulator@4";
		ldo3_reg = "/ocp/i2c@44e0b000/tps@24/regulators/regulator@5";
		ldo4_reg = "/ocp/i2c@44e0b000/tps@24/regulators/regulator@6";
		baseboard_eeprom = "/ocp/i2c@44e0b000/baseboard_eeprom@50";
		i2c1 = "/ocp/i2c@4802a000";
		i2c2 = "/ocp/i2c@4819c000";
		cape_eeprom0 = "/ocp/i2c@4819c000/cape_eeprom0@54";
		cape_eeprom1 = "/ocp/i2c@4819c000/cape_eeprom1@55";
		cape_eeprom2 = "/ocp/i2c@4819c000/cape_eeprom2@56";
		cape_eeprom3 = "/ocp/i2c@4819c000/cape_eeprom3@57";
		mmc1 = "/ocp/mmc@48060000";
		mmc2 = "/ocp/mmc@481d8000";
		mmc3 = "/ocp/mmc@47810000";
		wdt2 = "/ocp/wdt@44e35000";
		dcan0 = "/ocp/d_can@481cc000";
		dcan1 = "/ocp/d_can@481d0000";
		timer1 = "/ocp/timer@44e31000";
		timer2 = "/ocp/timer@48040000";
		timer3 = "/ocp/timer@48042000";
		timer4 = "/ocp/timer@48044000";
		timer5 = "/ocp/timer@48046000";
		timer6 = "/ocp/timer@48048000";
		timer7 = "/ocp/timer@4804a000";
		pruss = "/ocp/pruss@4a300000";
		spi0 = "/ocp/spi@48030000";
		spi1 = "/ocp/spi@481a0000";
		gpmc = "/ocp/gpmc@50000000";
		usb_otg_hs = "/ocp/usb@47400000";
		mac = "/ocp/ethernet@4a100000";
		davinci_mdio = "/ocp/ethernet@4a100000/mdio@4a101000";
		cpsw_emac0 = "/ocp/ethernet@4a100000/slave@4a100200";
		cpsw_emac1 = "/ocp/ethernet@4a100000/slave@4a100300";
		tscadc = "/ocp/tscadc@44e0d000";
		lcdc = "/ocp/lcdc@4830e000";
		epwmss0 = "/ocp/epwmss@48300000";
		ecap0 = "/ocp/epwmss@48300000/ecap@48300100";
		ehrpwm0 = "/ocp/epwmss@48300000/ehrpwm@48300200";
		epwmss1 = "/ocp/epwmss@48302000";
		ecap1 = "/ocp/epwmss@48302000/ecap@48302100";
		ehrpwm1 = "/ocp/epwmss@48302000/ehrpwm@48302200";
		epwmss2 = "/ocp/epwmss@48304000";
		ecap2 = "/ocp/epwmss@48304000/ecap@48304100";
		ehrpwm2 = "/ocp/epwmss@48304000/ehrpwm@48304200";
		sham = "/ocp/sham@53100000";
		aes = "/ocp/aes@53500000";
		mcasp0 = "/ocp/mcasp@48038000";
		mcasp1 = "/ocp/mcasp@4803C000";
		baseboard_beaglebone = "/bone_capemgr/baseboardmaps/board@0";
		baseboard_beaglebone_black = "/bone_capemgr/baseboardmaps/board@1";
		vmmcsd_fixed = "/fixedregulator@0";
	};
};
